# DP32G030 register map
File version: 1.0
CPU: CM0 r0p0, little endian, no MPU, no FPU, 4 interrupt priority bits
Registers are 32-bit, read-write, reset 0x0 unless marked. A register's access mark holds for its fields unless they carry their own. Offsets are from the block's base; [hi:lo] are bit positions; {n}, {i} and the like mark numbered series.

## PMU — Power management unit
Base 0x40000800
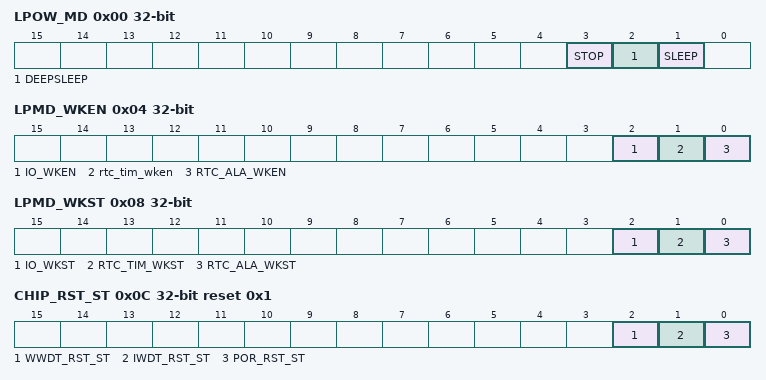
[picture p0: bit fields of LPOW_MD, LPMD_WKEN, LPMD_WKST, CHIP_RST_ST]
0x00 LPOW_MD — Low Power Mode Select Register
  [3] STOP — Write 1 to this register, the chip enters STOP mode
  [2] DEEPSLEEP — Write 1 to this register, the chip enters DEEPSLEEP mode, hardware clears it automatically
  [1] SLEEP — Write 1 to this register, the chip enters SLEEP mode, hardware clears it automatically
0x04 LPMD_WKEN — Low Power Wakeup Source Enable Register
  [2] IO_WKEN — IO wake-up enable in low-power mode 0: disable 1: Enable Note 1: Which IO has the wake-up function can be configured through the PORTA_WKE, PORTB_WKE, PORTC_WKE registers.
  [1] rtc_tim_wken — RTC time signal wake-up enable in low-power mode 1: RTC time signal with low-power wake-up function
  [0] RTC_ALA_WKEN — RTC alarm signal wake-up enable in low-power mode 1: RTC alarm signal with low-power wake-up function
0x08 LPMD_WKST — Low Power Wakeup Source Status Register
  [2] IO_WKST write-1-clears — IO wake-up flag in low-power mode 1: Wake on IO event 0: no IO event wakeup hardware set to 1, software write 1 clear
  [1] RTC_TIM_WKST write-1-clears — RTC time to wake up flag in low power mode 1: RTC time event wakeup hardware set to 1, software write 1 clear
  [0] RTC_ALA_WKST write-1-clears — RTC alarm clock wake-up flag in low-power mode 1: RTC alarm event wakeup hardware set to 1, software write 1 clear
0x0C CHIP_RST_ST reset 0x1 — Chip Reset Status Register
  [2] WWDT_RST_ST write-1-clears — WWDT Reset Status Flag Register 0: Indicates that no WWDT reset has occurred 1: Indicates a WWDT reset Write 1 Clear
  [1] IWDT_RST_ST write-1-clears — IWDT Reset Status Flag Register 0: Indicates that no IWDT reset has occurred. 1: Indicates an IWDT reset Write 1 Clear
  [0] POR_RST_ST write-1-clears — Power-on reset status flag register 0: Indicates no power-on reset 1: Indicates a power-on reset Write 1 clear
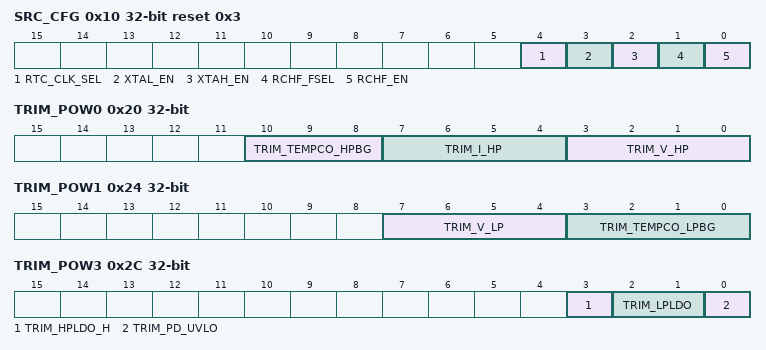
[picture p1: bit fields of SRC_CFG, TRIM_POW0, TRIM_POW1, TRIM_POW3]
0x10 SRC_CFG reset 0x3 — Clock Source Configuration Register
  [4] RTC_CLK_SEL — RTC Clock Selection 0: RCLF 1: XTAL
  [3] XTAL_EN — XTAL enable control bit 0: Close XTAL 1: Turn on XTAL
  [2] XTAH_EN — XTAH Enable Control Bit 0: Close XTAH 1: Turn on XTAH
  [1] RCHF_FSEL — RCHF Frequency selection control bit 0: 48MHz 1: 24 MHz
  [0] RCHF_EN — RCHF enable control bit 0: Close RCHF 1: Enable RCHF
0x20 TRIM_POW0 — POW0 Related Analog Modules TRIM register
  [10:8] TRIM_TEMPCO_HPBG — HPBG temperature trim bit
  [7:4] TRIM_I_HP — HPBG current trim bit
  [3:0] TRIM_V_HP — HPBG Voltage trim bit
0x24 TRIM_POW1 — POW1 Related Analog Modules TRIM register
  [7:4] TRIM_V_LP — LPBG Voltage trim bit
  [3:0] TRIM_TEMPCO_LPBG — LPBG temperature trim bit
0x28 TRIM_POW2 access not given — POW2 Related Analog Modules TRIM register
0x2C TRIM_POW3 — POW3 Related Analog Modules TRIM register
  [3] TRIM_HPLDO_H — HPLDO voltage adjusted to 1.264v 0: unchanged 1: Adjust upward to 1.264v
  [2:1] TRIM_LPLDO — LPLDO Voltage output trim bit 00: 1.1V 01: 1.0V 10: 0.9V 11: 0.8V
  [0] TRIM_PD_UVLO — UVLO33 trim bit 0: Under SLEEP, the chip resets when the supply voltage drops to 1.8V; the analog circuitry consumes an additional 0.6uA of power in this case; 1: Under SLEEP, the chip resets when the supply voltage drops to 1.3V (+-500mV deviation); the analog circuitry saves 0.6uA of power consumption;
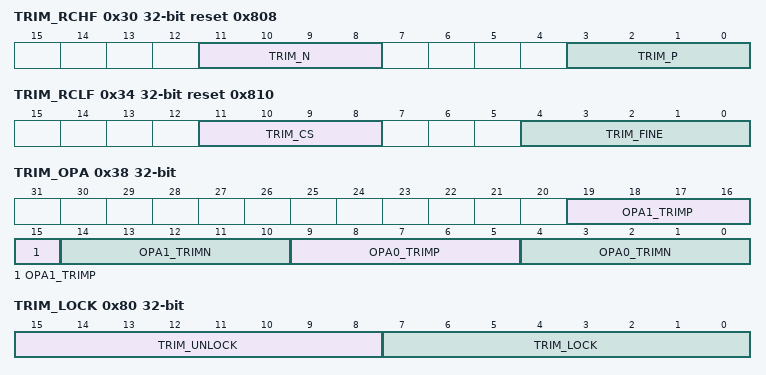
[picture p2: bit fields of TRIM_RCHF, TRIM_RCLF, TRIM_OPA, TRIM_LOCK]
0x30 TRIM_RCHF reset 0x808 — RCHF Clock Module TRIM Register
  [11:8] TRIM_N — RCHF N trim bit
  [3:0] TRIM_P — RCHF P trim bit
0x34 TRIM_RCLF reset 0x810 — RCLF Clock Module TRIM Register
  [11:8] TRIM_CS — RCLF CS trim bit (coarse trim bit)
  [4:0] TRIM_FINE — RCLF FINE trim bit (fine trim bit)
0x38 TRIM_OPA — OPA Module TRIM Register
  [19:15] OPA1_TRIMP — P-terminal TRIM bit of OPA1
  [14:10] OPA1_TRIMN — N-terminal TRIM bit of OPA1
  [9:5] OPA0_TRIMP — P-terminal TRIM bit of OPA0
  [4:0] OPA0_TRIMN — N-terminal TRIM bit of OPA0
0x3C TRIM_PLL — PLL Module TRIM Register
  [3:0] PLL_R_TRSIM — R value of PLL TRIM bit
0x80 TRIM_LOCK wo — TRIM Locks the registers
  [15:8] TRIM_UNLOCK — The corresponding TRIM configuration register can be rewritten by writing this register to 0xAA.
  [7:0] TRIM_LOCK — Writing this register to 0x55 prevents the corresponding TRIM configuration register from being rewritten, and is used to protect against accidental rewriting of TRIM registers.
{0x100+4i} DATA_BAK{i} access not given (i=0..3) — Non-power-off domain data backup register{i}
